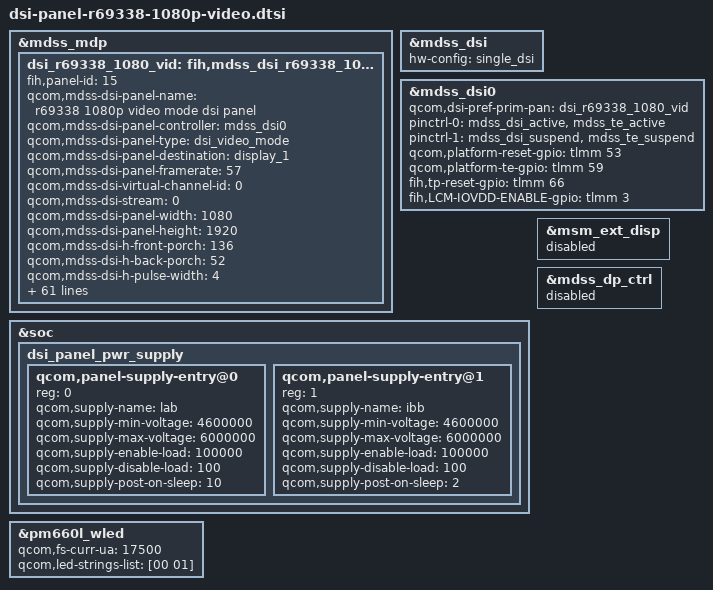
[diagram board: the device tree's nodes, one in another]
/* Copyright (c) 2013, The Linux Foundation. All rights reserved.
 *
 * This program is free software; you can redistribute it and/or modify
 * it under the terms of the GNU General Public License version 2 and
 * only version 2 as published by the Free Software Foundation.
 *
 * This program is distributed in the hope that it will be useful,
 * but WITHOUT ANY WARRANTY; without even the implied warranty of
 * MERCHANTABILITY or FITNESS FOR A PARTICULAR PURPOSE.  See the
 * GNU General Public License for more details.
 */

/*---------------------------------------------------------------------------
 * This file is autogenerated file using gcdb parser. Please do not edit it.
 * Update input XML file to add a new entry or update variable in this file
 * VERSION = "1.0"
 *---------------------------------------------------------------------------*/

&mdss_mdp {
		dsi_r69338_1080_vid: fih,mdss_dsi_r69338_1080p_video {
		fih,panel-id = <15>;
		qcom,mdss-dsi-panel-name = "r69338 1080p video mode dsi panel";
		qcom,mdss-dsi-panel-controller = <&mdss_dsi0>;
		qcom,mdss-dsi-panel-type = "dsi_video_mode";
		qcom,mdss-dsi-panel-destination = "display_1";
		qcom,mdss-dsi-panel-framerate = <57>;
		qcom,mdss-dsi-virtual-channel-id = <0>;
		qcom,mdss-dsi-stream = <0>;
		qcom,mdss-dsi-panel-width = <1080>;
		qcom,mdss-dsi-panel-height = <1920>;

		qcom,mdss-dsi-h-front-porch = <136>;
		qcom,mdss-dsi-h-back-porch = <52>;
		qcom,mdss-dsi-h-pulse-width = <4>;
		qcom,mdss-dsi-h-sync-skew = <0>;
		qcom,mdss-dsi-v-back-porch = <3>;
		qcom,mdss-dsi-v-front-porch = <4>;
		qcom,mdss-dsi-v-pulse-width = <1>;

		qcom,mdss-dsi-h-left-border = <0>;
		qcom,mdss-dsi-h-right-border = <0>;
		qcom,mdss-dsi-v-top-border = <0>;
		qcom,mdss-dsi-v-bottom-border = <0>;
		qcom,mdss-dsi-v-sync-pulse = <1>;
		qcom,mdss-dsi-bpp = <24>;
		/*qcom,mdss-dsi-color-order = <0>;*/
		qcom,mdss-dsi-underflow-color = <0xff>;
		qcom,mdss-dsi-border-color = <0>;
		qcom,mdss-dsi-on-command = [

				39 01 00 00 00 00 02 B0 02
				15 01 00 00 00 00 02 51 00 
				15 01 00 00 00 00 02 53 24 
				15 01 00 00 00 00 02 55 01
				05 01 00 00 14 00 02 29 00
				05 01 00 00 78 00 02 11 00
				];
		qcom,mdss-dsi-off-command = [
					05 01 00 00 02 00 02 28 00
					05 01 00 00 79 00 02 10 00
					];
		qcom,suspend-ulps-enabled;
		qcom,mdss-dsi-on-command-state = "dsi_lp_mode";
		qcom,mdss-dsi-off-command-state = "dsi_hs_mode";
		/*qcom,mdss-dsi-h-sync-pulse = <1>;*/
		qcom,mdss-dsi-h-sync-pulse = <5>;
		/*qcom,mdss-dsi-traffic-mode = <2>;*/
		qcom,mdss-dsi-traffic-mode = "non_burst_sync_event";
		qcom,mdss-dsi-lane-map = <0>;
		qcom,mdss-dsi-bllp-eof-power-mode;
		qcom,mdss-dsi-bllp-power-mode;
		qcom,mdss-dsi-lane-0-state;
		qcom,mdss-dsi-lane-1-state;
		qcom,mdss-dsi-lane-2-state;
		qcom,mdss-dsi-lane-3-state;	
		qcom,mdss-dsi-panel-status-check-mode = "reg_read";
		//HLT provide
		qcom,mdss-dsi-panel-timings = [D5 32 22 00 60 64 26 36 29 03 04 00];
		//qcom,mdss-dsi-panel-timings = [E6 38 26 00 68 6C 2A 3C 2C 03 04 00];
		//qcom,mdss-dsi-panel-timings = [6D 18 10 00 38 3E 12 1A 13 03 04 00];
		qcom,mdss-dsi-t-clk-post = <0x1e>;
		qcom,mdss-dsi-t-clk-pre = <0x38>;
		qcom,mdss-dsi-bl-min-level = <1>;
		qcom,mdss-dsi-bl-max-level = <4095>;
		/*qcom,mdss-dsi-dma-trigger = <4>;*/
		qcom,mdss-dsi-dma-trigger = "trigger_sw";
		/*qcom,mdss-dsi-mdp-trigger = <0>;*/
		qcom,mdss-dsi-mdp-trigger = "none";
		qcom,mdss-dsi-bl-pmic-control-type = "bl_ctrl_wled";
		/*	qcom,mdss-dsi-reset-sequence = <1 50>, <0 20>, <1 120>;*/
		/*qcom,mdss-pan-physical-width-dimension = <61>;*/
		/*qcom,mdss-pan-physical-height-dimension = <110>;*/
		qcom,mdss-dsi-reset-sequence = <1 5>, <0 5>, <1 100>;

		/*Add by ZZDC sunqiupeng for esd check START*/
		qcom,esd-check-enabled;
		qcom,mdss-dsi-panel-status-command = [06 01 00 01 00 00 01 0A];
		qcom,mdss-dsi-panel-status-command-state = "dsi_hs_mode";
		qcom,mdss-dsi-panel-status-value = <0x1C>;
		qcom,mdss-dsi-panel-on-check-value = <0x1C>;
		qcom,mdss-dsi-panel-status-read-length = <1>;
		qcom,mdss-dsi-panel-max-error-count = <3>;
		/*Add by ZZDC sunqiupeng for esd check END*/

		qcom,mdss-pan-physical-width-dimension = <68>;
		qcom,mdss-pan-physical-height-dimension = <120>;
		qcom,mdss-pan-physical-width-dimension-full = <6804>;
		qcom,mdss-pan-physical-height-dimension-full = <12096>;
	};
};

&dsi_r69338_1080_vid {
	qcom,mdss-dsi-panel-timings-phy-v2 = [23 1e 07 09 05 03 04 a0
		23 1e 07 09 05 03 04 a0
		23 1e 07 09 05 03 04 a0
		23 1e 07 09 05 03 04 a0
		23 19 07 08 05 03 04 a0];
	qcom,mdss-dsi-bl-pmic-control-type = "bl_ctrl_wled";
	qcom,mdss-dsi-bl-min-level = <1>;
	qcom,mdss-dsi-bl-max-level = <4095>;
	qcom,panel-supply-entries = <&dsi_panel_pwr_supply>;
};
&mdss_dsi {
	hw-config = "single_dsi";
};
&mdss_dsi0 {
	qcom,dsi-pref-prim-pan = <&dsi_r69338_1080_vid>;
	pinctrl-names = "mdss_default", "mdss_sleep";
	pinctrl-0 = <&mdss_dsi_active &mdss_te_active>;
	pinctrl-1 = <&mdss_dsi_suspend &mdss_te_suspend>;
	qcom,platform-reset-gpio = <&tlmm 53 0>;
	qcom,platform-te-gpio = <&tlmm 59 0>;
	fih,tp-reset-gpio = <&tlmm 66 0>;//add by zzdc@snow
	fih,LCM-IOVDD-ENABLE-gpio = <&tlmm 3 0>;
};
&soc {
	/delete-node/dsi_panel_pwr_supply;

	dsi_panel_pwr_supply: dsi_panel_pwr_supply {
		#address-cells = <1>;
		#size-cells = <0>;

		qcom,panel-supply-entry@0 {
			reg = <0>;
			qcom,supply-name = "lab";
			qcom,supply-min-voltage = <4600000>;
			qcom,supply-max-voltage = <6000000>;
			qcom,supply-enable-load = <100000>;
			qcom,supply-disable-load = <100>;
			qcom,supply-post-on-sleep = <10>;
		};

		qcom,panel-supply-entry@1 {
			reg = <1>;
			qcom,supply-name = "ibb";
			qcom,supply-min-voltage = <4600000>;
			qcom,supply-max-voltage = <6000000>;
			qcom,supply-enable-load = <100000>;
			qcom,supply-disable-load = <100>;
			qcom,supply-post-on-sleep = <2>;
		};
	};
};
&msm_ext_disp {
	status = "disabled";
};

&mdss_dp_ctrl {
	status = "disabled";
};

&pm660l_wled {
	qcom,fs-curr-ua = <17500>;
	qcom,led-strings-list = [00 01];
};
